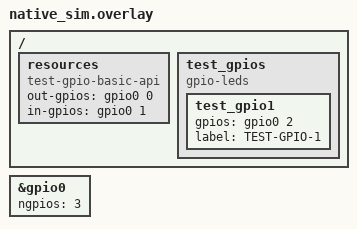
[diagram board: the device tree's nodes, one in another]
/*
 * Copyright (c) 2020 Friedt Professional Engineering Services, Inc
 *
 * SPDX-License-Identifier: Apache-2.0
 */

/ {
    resources {
        compatible = "test-gpio-basic-api";
        out-gpios = <&gpio0 0 0>; /* Pin 0 */
        in-gpios = <&gpio0 1 0>; /* Pin 1 */

    };

    test_gpios {
        compatible = "gpio-leds";
        test_gpio1 {
                gpios = <&gpio0 2 GPIO_ACTIVE_HIGH>;
                label = "TEST-GPIO-1";
        };
    };
};

// By default, native_sim has 2 GPIOs. Add another for testing.
&gpio0 {
    ngpios = <3>;
};
